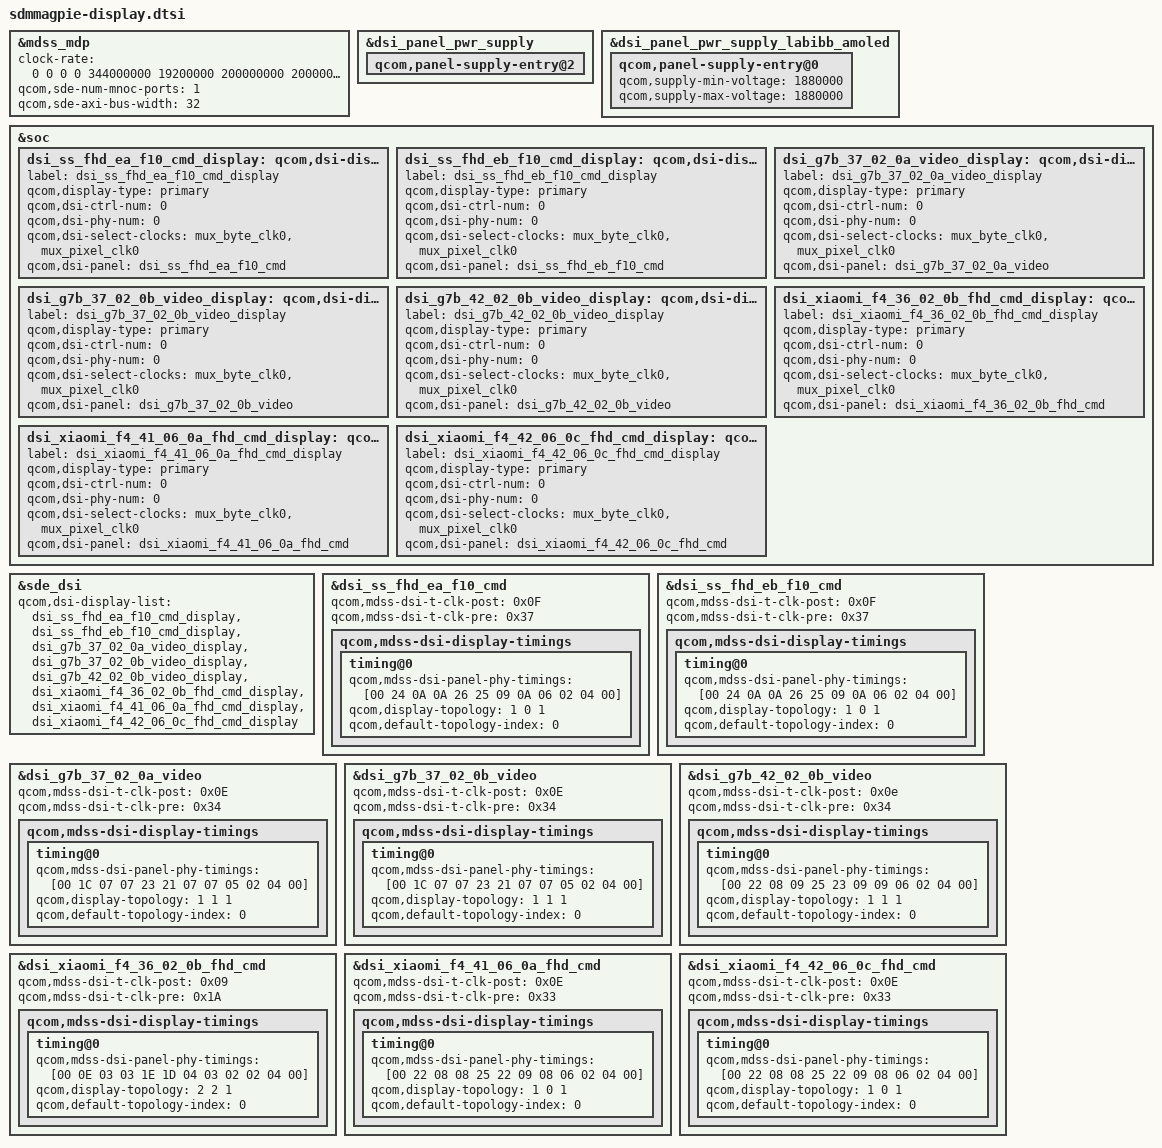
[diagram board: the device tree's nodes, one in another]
#include "dsi-panel-ss-fhd-ea-f10-cmd.dtsi"
#include "dsi-panel-ss-fhd-eb-f10-cmd.dtsi"
#include "dsi-panel-xiaomi-f4-36-02-0b-fhd-cmd.dtsi"
#include "dsi-panel-xiaomi-f4-41-06-0a-fhd-cmd.dtsi"
#include "dsi-panel-xiaomi-f4-42-06-0c-fhd-cmd.dtsi"
#include "dsi-panel-g7b-37-02-0a-dsc-video.dtsi"
#include "dsi-panel-g7b-37-02-0b-dsc-video.dtsi"
#include "dsi-panel-g7b-42-02-0b-dsc-video.dtsi"

#include "../sdmmagpie-sde-display.dtsi"

&mdss_mdp {
	clock-rate = <0 0 0 0 344000000 19200000 200000000
	  200000000>;
	qcom,sde-num-mnoc-ports = <1>;
	qcom,sde-axi-bus-width = <32>;
};

&dsi_panel_pwr_supply {
	qcom,panel-supply-entry@2 {
		/delete-property/ qcom,supply-post-on-sleep;
	};
};

&dsi_panel_pwr_supply_labibb_amoled {
	qcom,panel-supply-entry@0 {
		qcom,supply-min-voltage = <1880000>;
		qcom,supply-max-voltage = <1880000>;
	};
};

&soc {
	dsi_ss_fhd_ea_f10_cmd_display: qcom,dsi-display@22 {
		label = "dsi_ss_fhd_ea_f10_cmd_display";
		qcom,display-type = "primary";

		qcom,dsi-ctrl-num = <0>;
		qcom,dsi-phy-num = <0>;
		qcom,dsi-select-clocks = "mux_byte_clk0", "mux_pixel_clk0";

		qcom,dsi-panel = <&dsi_ss_fhd_ea_f10_cmd>;
	};

	dsi_ss_fhd_eb_f10_cmd_display: qcom,dsi-display@23 {
		label = "dsi_ss_fhd_eb_f10_cmd_display";
		qcom,display-type = "primary";

		qcom,dsi-ctrl-num = <0>;
		qcom,dsi-phy-num = <0>;
		qcom,dsi-select-clocks = "mux_byte_clk0", "mux_pixel_clk0";

		qcom,dsi-panel = <&dsi_ss_fhd_eb_f10_cmd>;
	};

	dsi_g7b_37_02_0a_video_display: qcom,dsi-display@24 {
		label = "dsi_g7b_37_02_0a_video_display";
		qcom,display-type = "primary";

		qcom,dsi-ctrl-num = <0>;
		qcom,dsi-phy-num = <0>;
		qcom,dsi-select-clocks = "mux_byte_clk0", "mux_pixel_clk0";

		qcom,dsi-panel = <&dsi_g7b_37_02_0a_video>;
	};

	dsi_g7b_37_02_0b_video_display: qcom,dsi-display@225{
		label = "dsi_g7b_37_02_0b_video_display";
		qcom,display-type = "primary";

		qcom,dsi-ctrl-num = <0>;
		qcom,dsi-phy-num = <0>;
		qcom,dsi-select-clocks = "mux_byte_clk0", "mux_pixel_clk0";

		qcom,dsi-panel = <&dsi_g7b_37_02_0b_video>;
	};

	dsi_g7b_42_02_0b_video_display: qcom,dsi-display@26 {
		label = "dsi_g7b_42_02_0b_video_display";
		qcom,display-type = "primary";

		qcom,dsi-ctrl-num = <0>;
		qcom,dsi-phy-num = <0>;
		qcom,dsi-select-clocks = "mux_byte_clk0", "mux_pixel_clk0";

		qcom,dsi-panel = <&dsi_g7b_42_02_0b_video>;
	};

	dsi_xiaomi_f4_36_02_0b_fhd_cmd_display: qcom,dsi-display@27 {
		label = "dsi_xiaomi_f4_36_02_0b_fhd_cmd_display";
		qcom,display-type = "primary";

		qcom,dsi-ctrl-num = <0>;
		qcom,dsi-phy-num = <0>;
		qcom,dsi-select-clocks = "mux_byte_clk0", "mux_pixel_clk0";

		qcom,dsi-panel = <&dsi_xiaomi_f4_36_02_0b_fhd_cmd>;
	};

	dsi_xiaomi_f4_41_06_0a_fhd_cmd_display: qcom,dsi-display@28 {
		 label = "dsi_xiaomi_f4_41_06_0a_fhd_cmd_display";
		 qcom,display-type = "primary";

		 qcom,dsi-ctrl-num = <0>;
		 qcom,dsi-phy-num = <0>;
		 qcom,dsi-select-clocks = "mux_byte_clk0", "mux_pixel_clk0";

		 qcom,dsi-panel = <&dsi_xiaomi_f4_41_06_0a_fhd_cmd>;
	 };

	dsi_xiaomi_f4_42_06_0c_fhd_cmd_display: qcom,dsi-display@29 {
		label = "dsi_xiaomi_f4_42_06_0c_fhd_cmd_display";
		qcom,display-type = "primary";

		qcom,dsi-ctrl-num = <0>;
		qcom,dsi-phy-num = <0>;
		qcom,dsi-select-clocks = "mux_byte_clk0", "mux_pixel_clk0";

		qcom,dsi-panel = <&dsi_xiaomi_f4_42_06_0c_fhd_cmd>;
	};
};

&sde_dsi {
	qcom,dsi-display-list =
		<&dsi_ss_fhd_ea_f10_cmd_display
		&dsi_ss_fhd_eb_f10_cmd_display
		&dsi_g7b_37_02_0a_video_display
		&dsi_g7b_37_02_0b_video_display
		&dsi_g7b_42_02_0b_video_display
		&dsi_xiaomi_f4_36_02_0b_fhd_cmd_display
		&dsi_xiaomi_f4_41_06_0a_fhd_cmd_display
		&dsi_xiaomi_f4_42_06_0c_fhd_cmd_display>;
};

&dsi_ss_fhd_ea_f10_cmd {
	qcom,mdss-dsi-t-clk-post = <0x0F>;
	qcom,mdss-dsi-t-clk-pre = <0x37>;

	qcom,mdss-dsi-display-timings {
		timing@0{
			qcom,mdss-dsi-panel-phy-timings = [00 24 0A 0A 26 25 09
					0A 06 02 04 00];
			qcom,display-topology = <1 0 1>;
			qcom,default-topology-index = <0>;
		};
	};
};

&dsi_ss_fhd_eb_f10_cmd {
	qcom,mdss-dsi-t-clk-post = <0x0F>;
	qcom,mdss-dsi-t-clk-pre = <0x37>;

	qcom,mdss-dsi-display-timings {
		timing@0{
			qcom,mdss-dsi-panel-phy-timings = [00 24 0A 0A 26 25 09
					0A 06 02 04 00];
			qcom,display-topology = <1 0 1>;
			qcom,default-topology-index = <0>;
		};
	};
};

&dsi_g7b_37_02_0a_video {
	qcom,mdss-dsi-t-clk-post = <0x0E>;
	qcom,mdss-dsi-t-clk-pre = <0x34>;

	qcom,mdss-dsi-display-timings {
		timing@0{
			qcom,mdss-dsi-panel-phy-timings = [00 1C 07 07 23 21 07
					07 05 02 04 00];
			qcom,display-topology = <1 1 1>;
			qcom,default-topology-index = <0>;
		};
	};
};

&dsi_g7b_37_02_0b_video {
	qcom,mdss-dsi-t-clk-post = <0x0E>;
	qcom,mdss-dsi-t-clk-pre = <0x34>;

	qcom,mdss-dsi-display-timings {
		timing@0{
			qcom,mdss-dsi-panel-phy-timings = [00 1C 07 07 23 21 07
					07 05 02 04 00];
			qcom,display-topology = <1 1 1>;
			qcom,default-topology-index = <0>;
		};
	};
};

&dsi_g7b_42_02_0b_video {
	qcom,mdss-dsi-t-clk-post = <0x0e>;
	qcom,mdss-dsi-t-clk-pre = <0x34>;

	qcom,mdss-dsi-display-timings {
		timing@0{
			qcom,mdss-dsi-panel-phy-timings = [00 22 08 09 25 23 09
					09 06 02 04 00];
			qcom,display-topology = <1 1 1>;
			qcom,default-topology-index = <0>;
		};
	};
};

&dsi_xiaomi_f4_36_02_0b_fhd_cmd {
	qcom,mdss-dsi-t-clk-post = <0x09>;
	qcom,mdss-dsi-t-clk-pre = <0x1A>;

	qcom,mdss-dsi-display-timings {
		timing@0{
			qcom,mdss-dsi-panel-phy-timings = [00 0E 03 03 1E 1D 04
					03 02 02 04 00];
			qcom,display-topology = <2 2 1>;
			qcom,default-topology-index = <0>;
		};
	};
};

&dsi_xiaomi_f4_41_06_0a_fhd_cmd {
	qcom,mdss-dsi-t-clk-post = <0x0E>;
	qcom,mdss-dsi-t-clk-pre = <0x33>;

	qcom,mdss-dsi-display-timings {
		timing@0{
			qcom,mdss-dsi-panel-phy-timings = [00 22 08 08 25 22 09
					08 06 02 04 00];
			qcom,display-topology = <1 0 1>;
			qcom,default-topology-index = <0>;
		};
	};
};

&dsi_xiaomi_f4_42_06_0c_fhd_cmd {
	qcom,mdss-dsi-t-clk-post = <0x0E>;
	qcom,mdss-dsi-t-clk-pre = <0x33>;

	qcom,mdss-dsi-display-timings {
		timing@0{
			qcom,mdss-dsi-panel-phy-timings = [00 22 08 08 25 22 09
					08 06 02 04 00];
			qcom,display-topology = <1 0 1>;
			qcom,default-topology-index = <0>;
		};
	};
};
